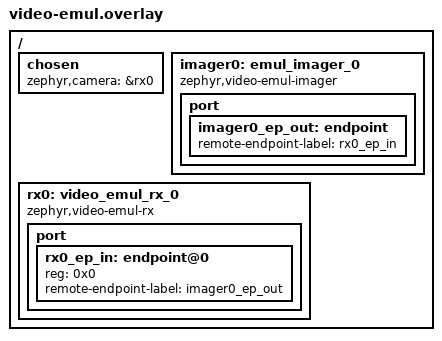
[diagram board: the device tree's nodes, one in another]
/*
 * Copyright (c) 2025 tinyVision.ai Inc.
 *
 * SPDX-License-Identifier: Apache-2.0
 */

/ {
	chosen {
		zephyr,camera = &rx0;
	};

	imager0: emul_imager_0 {
		compatible = "zephyr,video-emul-imager";

		port {
			imager0_ep_out: endpoint {
				remote-endpoint-label = "rx0_ep_in";
			};
		};
	};

	rx0: video_emul_rx_0 {
		compatible = "zephyr,video-emul-rx";

		port {
			#address-cells = <1>;
			#size-cells = <0>;

			rx0_ep_in: endpoint@0 {
				reg = <0x0>;
				remote-endpoint-label = "imager0_ep_out";
			};
		};
	};
};
